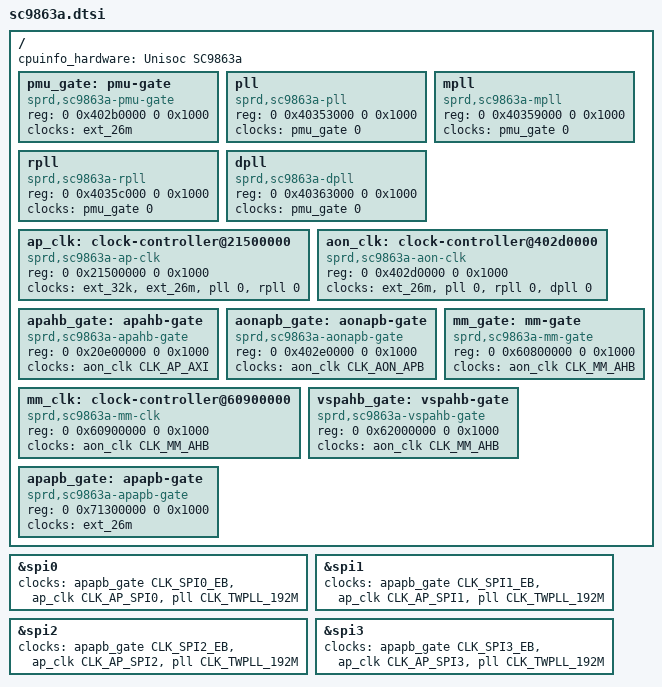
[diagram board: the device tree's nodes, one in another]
// SPDX-License-Identifier: (GPL-2.0+ OR MIT)
/*
 * Spreadtrum Sharkl3 platform DTS file
 *
 * Copyright (C) 2018, Spreadtrum Communications Inc.
 */


#include "sharkl3.dtsi"

/ {
	cpuinfo_hardware = "Unisoc SC9863a";

	pmu_gate: pmu-gate {
		compatible = "sprd,sc9863a-pmu-gate";
		/*sprd,syscon = <&pmu_apb_regs>;*/ /* 0x402b0000 */
		reg = <0 0x402b0000 0 0x1000>;
		clocks = <&ext_26m>;
		#clock-cells = <1>;
	};

	pll: pll {
		compatible = "sprd,sc9863a-pll";
		/*sprd,syscon = <&anlg_phy_g2_regs>;*/ /* 0x40353000 */
		reg = <0 0x40353000 0 0x1000>;
		clocks = <&pmu_gate 0>;
		#clock-cells = <1>;
	};

	mpll: mpll {
		compatible = "sprd,sc9863a-mpll";
		/*sprd,syscon = <&anlg_phy_g4_regs>;*/ /* 0x40359000 */
		reg = <0 0x40359000 0 0x1000>;
		clocks = <&pmu_gate 0>;
		#clock-cells = <1>;
	};

	rpll: rpll {
		compatible = "sprd,sc9863a-rpll";
		/*sprd,syscon = <&anlg_phy_g5_regs>;*/ /* 0x4035c000 */
		reg = <0 0x4035c000 0 0x1000>;
		clocks = <&pmu_gate 0>;
		#clock-cells = <1>;
	};

	dpll: dpll {
		compatible = "sprd,sc9863a-dpll";
		/*sprd,syscon = <&anlg_phy_g7_regs>;*/ /* 0x40363000 */
		reg = <0 0x40363000 0 0x1000>;
		clocks = <&pmu_gate 0>;
		#clock-cells = <1>;
	};

	ap_clk: clock-controller@21500000 {
		compatible = "sprd,sc9863a-ap-clk";
		reg = <0 0x21500000 0 0x1000>;
		clocks = <&ext_32k>, <&ext_26m>,
			 <&pll 0>, <&rpll 0>;
		#clock-cells = <1>;
	};

	aon_clk: clock-controller@402d0000 {
		compatible = "sprd,sc9863a-aon-clk";
		reg = <0 0x402d0000 0 0x1000>;
		clocks = <&ext_26m>, <&pll 0>,
			 <&rpll 0>, <&dpll 0>;
		#clock-cells = <1>;
	};

	apahb_gate: apahb-gate {
		compatible = "sprd,sc9863a-apahb-gate";
		/*sprd,syscon = <&ap_ahb_regs>;*/ /* 0x20e00000 */
		reg = <0 0x20e00000 0 0x1000>;
		clocks = <&aon_clk CLK_AP_AXI>;
		#clock-cells = <1>;
	};

	aonapb_gate: aonapb-gate {
		compatible = "sprd,sc9863a-aonapb-gate";
		/*sprd,syscon = <&aon_apb_regs>;*/ /* 0x402e0000 */
		reg = <0 0x402e0000 0 0x1000>;
		clocks = <&aon_clk CLK_AON_APB>;
		#clock-cells = <1>;
	};

	mm_gate: mm-gate {
		compatible = "sprd,sc9863a-mm-gate";
		/*sprd,syscon = <&mm_ahb_regs>;*/ /* 0x60800000 */
		reg = <0 0x60800000 0 0x1000>;
		clocks = <&aon_clk CLK_MM_AHB>;
		#clock-cells = <1>;
	};

	mm_clk: clock-controller@60900000 {
		compatible = "sprd,sc9863a-mm-clk";
		reg = <0 0x60900000 0 0x1000>; /* 0x60900000 */
		clocks = <&aon_clk CLK_MM_AHB>;
		#clock-cells = <1>;
	};

	vspahb_gate: vspahb-gate {
		compatible = "sprd,sc9863a-vspahb-gate";
		/*sprd,syscon = <&mm_vsp_ahb_regs>;*/ /* 0x62000000 */
		reg = <0 0x62000000 0 0x1000>;
		clocks = <&aon_clk CLK_MM_AHB>;
		#clock-cells = <1>;
	};

	apapb_gate: apapb-gate {
		compatible = "sprd,sc9863a-apapb-gate";
		/*sprd,syscon = <&ap_apb_regs>;*/ /* 0x71300000 */
		reg = <0 0x71300000 0 0x1000>;
		clocks = <&ext_26m>;
		#clock-cells = <1>;
	};
};

&spi0 {
	clock-names = "enable", "spi", "source";
	clocks = <&apapb_gate CLK_SPI0_EB>,
	<&ap_clk CLK_AP_SPI0>, <&pll CLK_TWPLL_192M>;
};

&spi1 {
	clock-names = "enable", "spi", "source";
	clocks = <&apapb_gate CLK_SPI1_EB>,
	<&ap_clk CLK_AP_SPI1>, <&pll CLK_TWPLL_192M>;
};

&spi2 {
	clock-names = "enable", "spi", "source";
	clocks = <&apapb_gate CLK_SPI2_EB>,
	<&ap_clk CLK_AP_SPI2>, <&pll CLK_TWPLL_192M>;
};

&spi3 {
	clock-names = "enable", "spi", "source";
	clocks = <&apapb_gate CLK_SPI3_EB>,
	<&ap_clk CLK_AP_SPI3>, <&pll CLK_TWPLL_192M>;
};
